VERSION "1.0"

NS_ :

BS_:

BU_: ECU Gateway

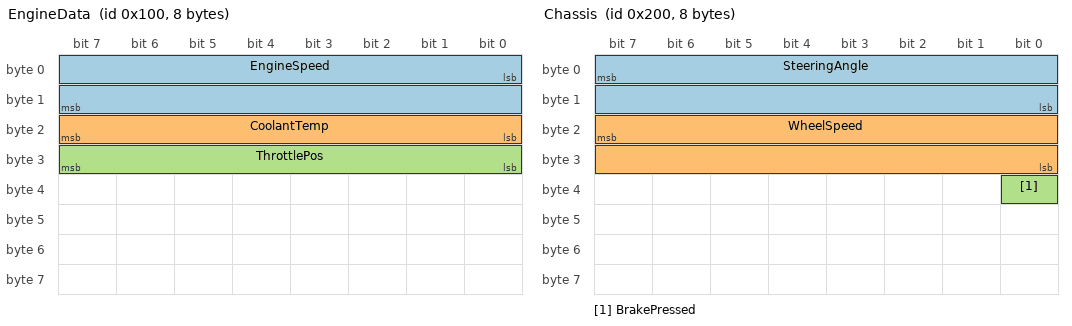
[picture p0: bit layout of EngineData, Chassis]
BO_ 256 EngineData: 8 ECU
 SG_ EngineSpeed : 0|16@1+ (0.25,0) [0|16383.75] "rpm" Gateway
 SG_ CoolantTemp : 16|8@1+ (1,-40) [-40|215] "degC" Gateway
 SG_ ThrottlePos : 24|8@1+ (0.4,0) [0|100] "%" Gateway

BO_ 512 Chassis: 8 Gateway
 SG_ SteeringAngle : 7|16@0- (0.1,0) [-780|780] "deg" ECU
 SG_ WheelSpeed : 23|16@0+ (0.01,0) [0|300] "km/h" ECU
 SG_ BrakePressed : 32|1@1+ (1,0) [0|1] "" ECU

BO_ 2566844672 CruiseControl: 8 ECU
 SG_ SetSpeed : 0|8@1+ (1,0) [0|250] "km/h" Gateway

BO_ 768 FdPayload: 12 ECU
 SG_ Counter : 0|32@1+ (1,0) [0|4294967295] "" Gateway
 SG_ Delta : 64|16@1- (0.5,0) [-16384|16383.5] "m" Gateway

BO_ 1024 Diagnostics: 8 ECU
 SG_ Page M : 0|8@1+ (1,0) [0|255] "" Gateway
 SG_ PageData m0 : 8|16@1+ (1,0) [0|65535] "" Gateway

BA_DEF_ BO_ "GenMsgCycleTime" INT 0 65535;
BA_ "GenMsgCycleTime" BO_ 256 10;
BA_ "GenMsgCycleTime" BO_ 512 20;
BA_ "GenMsgCycleTime" BO_ 2566844672 100;
BA_ "GenMsgCycleTime" BO_ 768 50;
